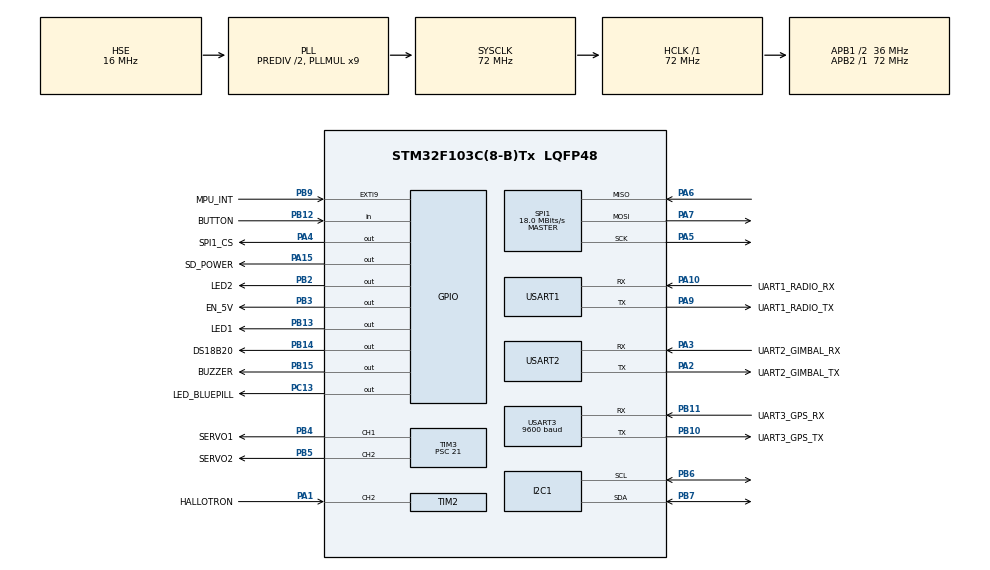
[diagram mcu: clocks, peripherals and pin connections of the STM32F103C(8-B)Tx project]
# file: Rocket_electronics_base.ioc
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Dma.Request0=USART1_TX
Dma.Request1=USART1_RX
Dma.USART1_RX.1.Direction=DMA_PERIPH_TO_MEMORY
Dma.USART1_RX.1.Instance=DMA1_Channel5
Dma.USART1_RX.1.MemDataAlignment=DMA_MDATAALIGN_BYTE
Dma.USART1_RX.1.MemInc=DMA_MINC_ENABLE
Dma.USART1_RX.1.Mode=DMA_NORMAL
Dma.USART1_RX.1.PeriphDataAlignment=DMA_PDATAALIGN_BYTE
Dma.USART1_RX.1.PeriphInc=DMA_PINC_DISABLE
Dma.USART1_RX.1.Priority=DMA_PRIORITY_LOW
Dma.USART1_TX.0.Direction=DMA_MEMORY_TO_PERIPH
Dma.USART1_TX.0.Instance=DMA1_Channel4
Dma.USART1_TX.0.MemDataAlignment=DMA_MDATAALIGN_BYTE
Dma.USART1_TX.0.MemInc=DMA_MINC_ENABLE
Dma.USART1_TX.0.Mode=DMA_NORMAL
Dma.USART1_TX.0.PeriphDataAlignment=DMA_PDATAALIGN_BYTE
Dma.USART1_TX.0.PeriphInc=DMA_PINC_DISABLE
Dma.USART1_TX.0.Priority=DMA_PRIORITY_LOW
Mcu.Family=STM32F1
Mcu.Name=STM32F103C(8-B)Tx
Mcu.Package=LQFP48
NVIC.DMA1_Channel4_IRQn=true\:0\:0\:false\:false\:true\:false\:true
NVIC.DMA1_Channel5_IRQn=true\:0\:0\:false\:false\:true\:false\:true
NVIC.EXTI9_5_IRQn=true\:0\:0\:false\:false\:true\:true\:true
NVIC.PriorityGroup=NVIC_PRIORITYGROUP_4
NVIC.TIM2_IRQn=true\:0\:0\:false\:false\:true\:true\:true
NVIC.TIM4_IRQn=true\:0\:0\:false\:false\:true\:true\:true
NVIC.USART1_IRQn=true\:0\:0\:false\:false\:true\:true\:true
NVIC.USART2_IRQn=true\:5\:0\:true\:false\:true\:true\:true
NVIC.USART3_IRQn=true\:5\:0\:true\:false\:true\:true\:true
PA1.GPIO_Label=HALLOTRON
PA1.Signal=S_TIM2_CH2
PA10.GPIO_Label=UART1_RADIO_RX
PA10.Mode=Asynchronous
PA10.Signal=USART1_RX
PA13.Mode=Serial_Wire
PA13.Signal=SYS_JTMS-SWDIO
PA14.Mode=Serial_Wire
PA14.Signal=SYS_JTCK-SWCLK
PA15.GPIO_Label=SD_POWER
PA15.GPIO_PuPd=GPIO_NOPULL
PA15.PinState=GPIO_PIN_SET
PA15.Signal=GPIO_Output
PA2.GPIO_Label=UART2_GIMBAL_TX
PA2.Mode=Asynchronous
PA2.Signal=USART2_TX
PA3.GPIO_Label=UART2_GIMBAL_RX
PA3.Mode=Asynchronous
PA3.Signal=USART2_RX
PA4.GPIO_Label=SPI1_CS
PA4.GPIO_PuPd=GPIO_NOPULL
PA4.PinState=GPIO_PIN_SET
PA4.Signal=GPIO_Output
PA5.Mode=Full_Duplex_Master
PA5.Signal=SPI1_SCK
PA6.Mode=Full_Duplex_Master
PA6.Signal=SPI1_MISO
PA7.Mode=Full_Duplex_Master
PA7.Signal=SPI1_MOSI
PA9.GPIO_Label=UART1_RADIO_TX
PA9.Mode=Asynchronous
PA9.Signal=USART1_TX
PB10.GPIO_Label=UART3_GPS_TX
PB10.Mode=Asynchronous
PB10.Signal=USART3_TX
PB11.GPIO_Label=UART3_GPS_RX
PB11.Mode=Asynchronous
PB11.Signal=USART3_RX
PB12.GPIO_Label=BUTTON
PB12.GPIO_PuPd=GPIO_PULLUP
PB12.Signal=GPIO_Input
PB13.GPIO_Label=LED1
PB13.Signal=GPIO_Output
PB14.GPIO_Label=DS18B20
PB14.GPIO_ModeDefaultOutputPP=GPIO_MODE_OUTPUT_OD
PB14.Signal=GPIO_Output
PB15.GPIO_Label=BUZZER
PB15.Signal=GPIO_Output
PB2.GPIO_Label=LED2
PB2.PinState=GPIO_PIN_RESET
PB2.Signal=GPIO_Output
PB3.GPIO_Label=EN_5V
PB3.Signal=GPIO_Output
PB4.GPIO_Label=SERVO1
PB4.Signal=S_TIM3_CH1
PB5.GPIO_Label=SERVO2
PB5.Signal=S_TIM3_CH2
PB6.Mode=I2C
PB6.Signal=I2C1_SCL
PB7.Mode=I2C
PB7.Signal=I2C1_SDA
PB9.GPIO_Label=MPU_INT
PB9.GPIO_ModeDefaultEXTI=GPIO_MODE_IT_FALLING
PB9.GPIO_PuPd=GPIO_PULLUP
PB9.Signal=GPXTI9
PC13-TAMPER-RTC.GPIO_Label=LED_BLUEPILL
PC13-TAMPER-RTC.Signal=GPIO_Output
PD0-OSC_IN.Mode=HSE-External-Oscillator
PD0-OSC_IN.Signal=RCC_OSC_IN
PD1-OSC_OUT.Mode=HSE-External-Oscillator
PD1-OSC_OUT.Signal=RCC_OSC_OUT
ProjectManager.HeapSize=0x200
ProjectManager.StackSize=0x400
ProjectManager.TargetToolchain=SW4STM32
RCC.AHBFreq_Value=72000000
RCC.APB1CLKDivider=RCC_HCLK_DIV2
RCC.APB1Freq_Value=36000000
RCC.APB1TimFreq_Value=72000000
RCC.APB2Freq_Value=72000000
RCC.APB2TimFreq_Value=72000000
RCC.HCLKFreq_Value=72000000
RCC.HSEDivPLL=RCC_HSE_PREDIV_DIV2
RCC.HSE_VALUE=16000000
RCC.PLLMUL=RCC_PLL_MUL9
RCC.PLLSourceVirtual=RCC_PLLSOURCE_HSE
RCC.SYSCLKFreq_VALUE=72000000
RCC.SYSCLKSource=RCC_SYSCLKSOURCE_PLLCLK
RCC.USBFreq_Value=48000000
RCC.USBPrescaler=RCC_USBCLKSOURCE_PLL_DIV1_5
RTC.Format=RTC_FORMAT_BIN
SH.S_TIM2_CH2.0=TIM2_CH2,Input_Capture2_from_TI2
SH.S_TIM3_CH1.0=TIM3_CH1,PWM Generation1 CH1
SH.S_TIM3_CH2.0=TIM3_CH2,PWM Generation2 CH2
SPI1.BaudRatePrescaler=SPI_BAUDRATEPRESCALER_4
SPI1.CalculateBaudRate=18.0 MBits/s
SPI1.Direction=SPI_DIRECTION_2LINES
SPI1.Mode=SPI_MODE_MASTER
SPI1.VirtualType=VM_MASTER
TIM1.Period=1
TIM1.Prescaler=17
TIM2.Channel-Input_Capture2_from_TI2=TIM_CHANNEL_2
TIM2.ICPolarity_CH2=TIM_INPUTCHANNELPOLARITY_FALLING
TIM2.Period=50000
TIM2.Prescaler=7200
TIM3.Channel-PWM\ Generation1\ CH1=TIM_CHANNEL_1
TIM3.Channel-PWM\ Generation2\ CH2=TIM_CHANNEL_2
TIM3.Period=65535
TIM3.Prescaler=21
TIM4.Channel-Output\ Compare1\ No\ Output=TIM_CHANNEL_1
TIM4.Channel-Output\ Compare2\ No\ Output=TIM_CHANNEL_2
TIM4.Channel-Output\ Compare3\ No\ Output=TIM_CHANNEL_3
TIM4.Period=10000
TIM4.Prescaler=48000
TIM4.Pulse-Output\ Compare1\ No\ Output=500
TIM4.Pulse-Output\ Compare2\ No\ Output=1300
TIM4.Pulse-Output\ Compare3\ No\ Output=9800
USART1.VirtualMode=VM_ASYNC
USART2.VirtualMode=VM_ASYNC
USART3.BaudRate=9600
USART3.VirtualMode=VM_ASYNC
VP_FATFS_VS_Generic.Mode=User_defined
VP_RTC_No_RTC_Output.Mode=RTC_OUT_NO
VP_RTC_VS_RTC_Activate.Mode=RTC_Enabled
VP_TIM1_VS_ClockSourceINT.Mode=Internal
VP_TIM2_VS_ClockSourceINT.Mode=Internal
VP_TIM3_VS_ClockSourceINT.Mode=Internal
VP_TIM4_VS_ClockSourceINT.Mode=Internal
VP_TIM4_VS_no_output1.Mode=Output Compare1 No Output
VP_TIM4_VS_no_output2.Mode=Output Compare2 No Output
VP_TIM4_VS_no_output3.Mode=Output Compare3 No Output
board=custom

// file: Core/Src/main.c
/* USER CODE BEGIN Header */
/**
  ******************************************************************************
  * @file           : main.c
  * @brief          : Main program body
  ******************************************************************************
  * This notice applies to any and all portions of this file
  * that are not between comment pairs USER CODE BEGIN and
  * USER CODE END. Other portions of this file, whether
  * inserted by the user or by software development tools
  * are owned by their respective copyright owners.
  *
  * Copyright (c) 2018 STMicroelectronics International N.V.
  * All rights reserved.
  *
  * Redistribution and use in source and binary forms, with or without
  * modification, are permitted, provided that the following conditions are met:
  *
  * 1. Redistribution of source code must retain the above copyright notice,
  *    this list of conditions and the following disclaimer.
  * 2. Redistributions in binary form must reproduce the above copyright notice,
  *    this list of conditions and the following disclaimer in the documentation
  *    and/or other materials provided with the distribution.
  * 3. Neither the name of STMicroelectronics nor the names of other
  *    contributors to this software may be used to endorse or promote products
  *    derived from this software without specific written permission.
  * 4. This software, including modifications and/or derivative works of this
  *    software, must execute solely and exclusively on microcontroller or
  *    microprocessor devices manufactured by or for STMicroelectronics.
  * 5. Redistribution and use of this software other than as permitted under
  *    this license is void and will automatically terminate your rights under
  *    this license.
  *
  * THIS SOFTWARE IS PROVIDED BY STMICROELECTRONICS AND CONTRIBUTORS "AS IS"
  * AND ANY EXPRESS, IMPLIED OR STATUTORY WARRANTIES, INCLUDING, BUT NOT
  * LIMITED TO, THE IMPLIED WARRANTIES OF MERCHANTABILITY, FITNESS FOR A
  * PARTICULAR PURPOSE AND NON-INFRINGEMENT OF THIRD PARTY INTELLECTUAL PROPERTY
  * RIGHTS ARE DISCLAIMED TO THE FULLEST EXTENT PERMITTED BY LAW. IN NO EVENT
  * SHALL STMICROELECTRONICS OR CONTRIBUTORS BE LIABLE FOR ANY DIRECT, INDIRECT,
  * INCIDENTAL, SPECIAL, EXEMPLARY, OR CONSEQUENTIAL DAMAGES (INCLUDING, BUT NOT
  * LIMITED TO, PROCUREMENT OF SUBSTITUTE GOODS OR SERVICES; LOSS OF USE, DATA,
  * OR PROFITS; OR BUSINESS INTERRUPTION) HOWEVER CAUSED AND ON ANY THEORY OF
  * LIABILITY, WHETHER IN CONTRACT, STRICT LIABILITY, OR TORT (INCLUDING
  * NEGLIGENCE OR OTHERWISE) ARISING IN ANY WAY OUT OF THE USE OF THIS SOFTWARE,
  * EVEN IF ADVISED OF THE POSSIBILITY OF SUCH DAMAGE.
  *
  ******************************************************************************
  */
/* USER CODE END Header */

#include "main.h"
#include "dma.h"
#include "fatfs.h"
#include "i2c.h"
#include "rtc.h"
#include "spi.h"
#include "tim.h"
#include "usart.h"
#include "gpio.h"

/* USER CODE BEGIN Includes */
//#include <TLE4905G/tle4905.h>
//#include <HAL_Callbacks/callbacks.h>
#include "cansat_includes.h"
/* USER CODE END Includes */

void SystemClock_Config(void);

int main(void)
{

  /* MCU Configuration--------------------------------------------------------*/

  /* Reset of all peripherals, Initializes the Flash interface and the Systick. */
  HAL_Init();

  /* Configure the system clock */
  SystemClock_Config();

  /* Initialize all configured peripherals */
  MX_GPIO_Init();
  MX_DMA_Init();
  MX_USART1_UART_Init();
  MX_I2C1_Init();
  MX_USART2_UART_Init();
  MX_USART3_UART_Init();
  MX_SPI1_Init();
  MX_TIM3_Init();
  MX_RTC_Init();
  MX_TIM2_Init();
  MX_FATFS_Init();
  MX_TIM1_Init();
  MX_TIM4_Init();
  /* USER CODE BEGIN 2 */
  //HAL_TIM_OC_Start_IT(&htim4, TIM_CHANNEL_1);
  //HAL_TIM_OC_Start_IT(&htim4, TIM_CHANNEL_2);
  //HAL_TIM_OC_Start_IT(&htim4, TIM_CHANNEL_3);
  //HAL_TIM_OC_Start_IT(&htim4, TIM_CHANNEL_4);

  //stateBootFunction();

  /* USER CODE END 2 */

  /* Infinite loop */
	while (1)
	{

	}
}

void SystemClock_Config(void)
{
  RCC_OscInitTypeDef RCC_OscInitStruct = {0};
  RCC_ClkInitTypeDef RCC_ClkInitStruct = {0};
  RCC_PeriphCLKInitTypeDef PeriphClkInit = {0};

  /**Initializes the CPU, AHB and APB busses clocks
  */
  RCC_OscInitStruct.OscillatorType = RCC_OSCILLATORTYPE_LSI|RCC_OSCILLATORTYPE_HSE;
  RCC_OscInitStruct.HSEState = RCC_HSE_ON;
  RCC_OscInitStruct.HSEPredivValue = RCC_HSE_PREDIV_DIV2;
  RCC_OscInitStruct.HSIState = RCC_HSI_ON;
  RCC_OscInitStruct.LSIState = RCC_LSI_ON;
  RCC_OscInitStruct.PLL.PLLState = RCC_PLL_ON;
  RCC_OscInitStruct.PLL.PLLSource = RCC_PLLSOURCE_HSE;
  RCC_OscInitStruct.PLL.PLLMUL = RCC_PLL_MUL9;
  if (HAL_RCC_OscConfig(&RCC_OscInitStruct) != HAL_OK)
  {
    Error_Handler();
  }
  /**Initializes the CPU, AHB and APB busses clocks
  */
  RCC_ClkInitStruct.ClockType = RCC_CLOCKTYPE_HCLK|RCC_CLOCKTYPE_SYSCLK
                              |RCC_CLOCKTYPE_PCLK1|RCC_CLOCKTYPE_PCLK2;
  RCC_ClkInitStruct.SYSCLKSource = RCC_SYSCLKSOURCE_PLLCLK;
  RCC_ClkInitStruct.AHBCLKDivider = RCC_SYSCLK_DIV1;
  RCC_ClkInitStruct.APB1CLKDivider = RCC_HCLK_DIV2;
  RCC_ClkInitStruct.APB2CLKDivider = RCC_HCLK_DIV1;

  if (HAL_RCC_ClockConfig(&RCC_ClkInitStruct, FLASH_LATENCY_2) != HAL_OK)
  {
    Error_Handler();
  }
  PeriphClkInit.PeriphClockSelection = RCC_PERIPHCLK_RTC;
  PeriphClkInit.RTCClockSelection = RCC_RTCCLKSOURCE_LSI;
  if (HAL_RCCEx_PeriphCLKConfig(&PeriphClkInit) != HAL_OK)
  {
    Error_Handler();
  }
}

void Error_Handler(void)
{
}

/************************ (C) COPYRIGHT STMicroelectronics *****END OF FILE****/
